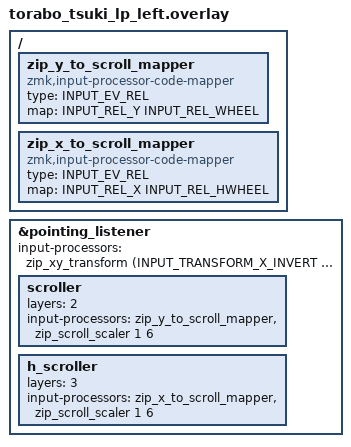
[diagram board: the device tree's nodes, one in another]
#include "torabo_tsuki_lp.dtsi"
#include <input/processors.dtsi>
#include <dt-bindings/zmk/input_transform.h>

/ {
    zip_y_to_scroll_mapper: zip_y_to_scroll_mapper {
        compatible = "zmk,input-processor-code-mapper";
        #input-processor-cells = <0>;
        type = <INPUT_EV_REL>;
        map = <INPUT_REL_Y INPUT_REL_WHEEL>;
    };

    zip_x_to_scroll_mapper: zip_x_to_scroll_mapper {
        compatible = "zmk,input-processor-code-mapper";
        #input-processor-cells = <0>;
        type = <INPUT_EV_REL>;
        map = <INPUT_REL_X INPUT_REL_HWHEEL>;
    };
};

&pointing_listener {
    input-processors = <&zip_xy_transform (INPUT_TRANSFORM_X_INVERT | INPUT_TRANSFORM_Y_INVERT)>;

    scroller {
        layers = <2>;
        input-processors = <&zip_y_to_scroll_mapper>, <&zip_scroll_scaler 1 6>;
    };

    h_scroller {
        layers = <3>;
        input-processors = <&zip_x_to_scroll_mapper>, <&zip_scroll_scaler 1 6>;
    };
};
